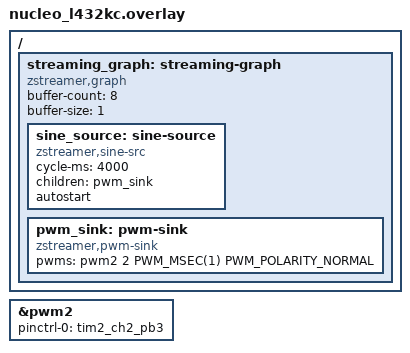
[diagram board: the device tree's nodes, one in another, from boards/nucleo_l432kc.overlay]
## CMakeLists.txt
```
# Copyright (c) 2026 sharonthecreator
# SPDX-License-Identifier: Apache-2.0

cmake_minimum_required(VERSION 3.20.0)
find_package(Zephyr REQUIRED HINTS $ENV{ZEPHYR_BASE})
project(sine2pwm)

target_sources(app PRIVATE src/main.c)
```

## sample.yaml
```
# Copyright (c) 2026 sharonthecreator
# SPDX-License-Identifier: Apache-2.0

sample:
  name: Sine wave to PWM
  description: |
    Demonstrates a sine-src → pwm-sink streaming pipeline that drives
    an LED brightness via PWM using a time-based sine wave.
tests:
  sample.zstreamer.sine2pwm:
    tags: zstreamer
    platform_allow: nucleo_l432kc
```

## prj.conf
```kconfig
# Copyright (c) 2026 sharonthecreator
# SPDX-License-Identifier: Apache-2.0

CONFIG_ZSTREAMER=y
CONFIG_ZSTREAMER_TEST_SINE_SRC=y
CONFIG_ZSTREAMER_PWM_SINK=y
CONFIG_PWM=y
CONFIG_LOG=y
```

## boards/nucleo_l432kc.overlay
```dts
/*
 * Copyright (c) 2026 sharonthecreator
 * SPDX-License-Identifier: Apache-2.0
 *
 * Sine wave generator to pwm (led) sink on Nucleo L432KC.
 */

/ {
	streaming_graph: streaming-graph {
		compatible = "zstreamer,graph";
		buffer-count = <8>;
		buffer-size = <1>;

		sine_source: sine-source {
			compatible = "zstreamer,sine-src";
			cycle-ms = <4000>;
			children = <&pwm_sink>;
			autostart;
		};

		pwm_sink: pwm-sink {
			compatible = "zstreamer,pwm-sink";
			pwms = <&pwm2 2 PWM_MSEC(1) PWM_POLARITY_NORMAL>;
		};
	};
};


&pwm2 {
	status = "okay";
	pinctrl-0 = <&tim2_ch2_pb3>;
	pinctrl-names = "default";
};
```

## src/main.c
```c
/*
 * Copyright (c) 2026 sharonthecreator
 * SPDX-License-Identifier: Apache-2.0
 */

#include <zephyr/device.h>
#include <zephyr/kernel.h>
#include <zephyr/logging/log.h>

#include <zstreamer/source.h>

LOG_MODULE_REGISTER(sine2pwm, LOG_LEVEL_INF);

#define SRC_NODE DT_NODELABEL(sine_source)

int main(void) {
  const struct device *src = DEVICE_DT_GET(SRC_NODE);
  int ret;

  if (!device_is_ready(src)) {
    LOG_ERR("source device not ready");
    return -ENODEV;
  }

  ret = zstreamer_source_start(src);
  if (ret) {
    LOG_ERR("failed to start pipeline: %d", ret);
    return ret;
  }

  LOG_INF("sine2pwm pipeline running");
  return 0;
}
```
